VERSION "vcansim"

NS_ :

BS_:

BU_: MotorECU ABSECU Monitor

BO_ 256 MotorStatus: 3 MotorECU
 SG_ RPM         : 0|16@1+ (0.5,0)   [0|8000]  "rpm"  Monitor
 SG_ Temperature : 16|8@1+ (1,-40)   [-40|150] "degC" Monitor

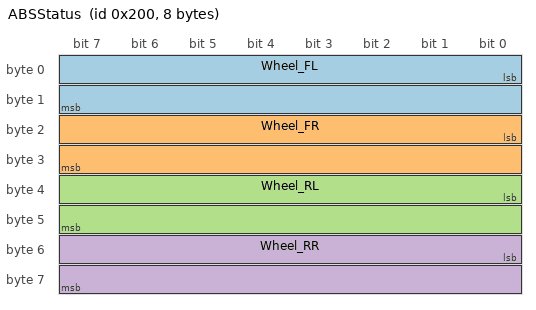
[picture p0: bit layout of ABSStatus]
BO_ 512 ABSStatus: 8 ABSECU
 SG_ Wheel_FL : 0|16@1+  (0.1,0) [0|300] "km/h" Monitor
 SG_ Wheel_FR : 16|16@1+ (0.1,0) [0|300] "km/h" Monitor
 SG_ Wheel_RL : 32|16@1+ (0.1,0) [0|300] "km/h" Monitor
 SG_ Wheel_RR : 48|16@1+ (0.1,0) [0|300] "km/h" Monitor

BO_ 768 MotorControl: 2 Monitor
 SG_ TargetRPM : 0|16@1+ (0.5,0) [0|8000] "rpm" MotorECU
